VERSION ""

NS_ :

BS_: 500

BU_: Vector__XXX

BO_ 201 MSG_0C9: 7 Vector__XXX
 SG_ Accelerator_Pedal_Position : 24|8@0+ (0.392157,0) [0|100.000035] "%" Vector__XXX
 SG_ Engine_Speed : 40|16@0+ (0.25,0) [0|10000] "rpm" Vector__XXX

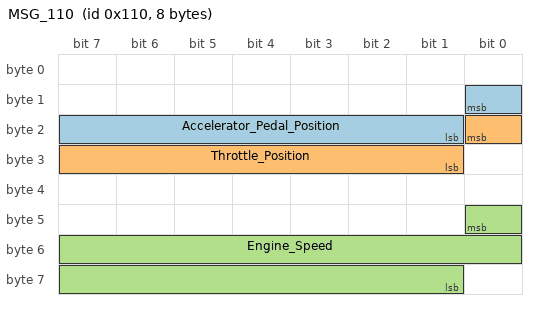
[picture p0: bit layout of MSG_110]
BO_ 272 MSG_110: 8 Vector__XXX
 SG_ Accelerator_Pedal_Position : 8|8@0+ (0.390625,0) [0|100] "%" Vector__XXX
 SG_ Throttle_Position : 16|8@0+ (0.392157,0) [0|100] "%" Vector__XXX
 SG_ Engine_Speed : 40|16@0+ (0.25,0) [0|7000] "rpm" Vector__XXX

BO_ 384 MSG_180: 4 Vector__XXX
 SG_ Steering_Angle : 32|16@0- (0.0625,0) [-540|540] "��" Vector__XXX

BO_ 501 MSG_1F5: 8 Vector__XXX
 SG_ Gear : 56|4@0+ (1,0) [0|15] "" Vector__XXX

BO_ 640 MSG_280: 8 Vector__XXX
 SG_ Wheel_Speed_FL_kph : 0|16@0+ (0.0322,0) [0|402.5] "km/h" Vector__XXX
 SG_ Wheel_Speed_FL_mph : 0|16@0+ (0.02,0) [0|250] "mph" Vector__XXX
 SG_ Wheel_Speed_RL_kph : 16|16@0+ (0.0322,0) [0|402.5] "km/h" Vector__XXX
 SG_ Wheel_Speed_RL_mph : 16|16@0+ (0.02,0) [0|250] "mph" Vector__XXX
 SG_ Wheel_Speed_FR_kph : 32|16@0+ (0.0322,0) [0|402.5] "km/h" Vector__XXX
 SG_ Wheel_Speed_FR_mph : 32|16@0+ (0.02,0) [0|250] "mph" Vector__XXX
 SG_ Wheel_Speed_RR_kph : 48|16@0+ (0.0322,0) [0|402.5] "km/h" Vector__XXX
 SG_ Wheel_Speed_RR_mph : 48|16@0+ (0.02,0) [0|250] "mph" Vector__XXX

BO_ 768 MSG_300: 6 Vector__XXX
 SG_ Oil_Temperature : 24|8@1+ (1,-60) [-60|192] "��C" Vector__XXX

BO_ 800 MSG_320: 8 Vector__XXX
 SG_ Gear_Requested : 40|8@0+ (1,0) [0|255] "" Vector__XXX
 SG_ Gear : 48|8@0+ (1,0) [0|255] "" Vector__XXX

BO_ 1217 MSG_4C1: 5 Vector__XXX
 SG_ Coolant_Temperature : 40|8@0+ (1,-40) [-40|215] "��C" Vector__XXX

BO_ 1225 MSG_4C9: 4 Vector__XXX
 SG_ Transmission_Oil_Temperature : 48|8@0+ (1,-40) [-40|215] "��C" Vector__XXX

BO_ 1296 MSG_510: 8 Vector__XXX
 SG_ Air_Temperature : 40|8@0+ (1,-40) [-40|215] "��C" Vector__XXX
 SG_ Coolant_Temperature : 48|8@0+ (1,-40) [-40|215] "��C" Vector__XXX
